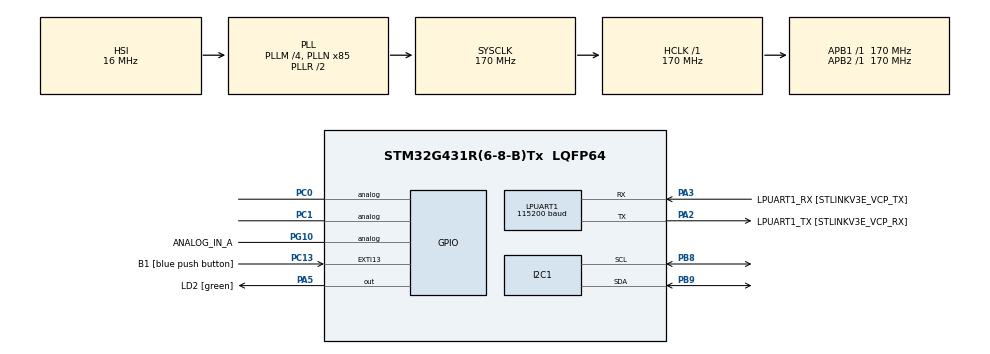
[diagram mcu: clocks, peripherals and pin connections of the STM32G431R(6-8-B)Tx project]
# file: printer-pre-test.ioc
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I2C1.Timing=0x30A0A7FB
LPUART1.BaudRate=115200
LPUART1.WordLength=UART_WORDLENGTH_8B
Mcu.Family=STM32G4
Mcu.Name=STM32G431R(6-8-B)Tx
Mcu.Package=LQFP64
NVIC.PriorityGroup=NVIC_PRIORITYGROUP_4
PA13.GPIO_Label=T_SWDIO
PA13.Mode=Serial_Wire
PA13.Signal=SYS_JTMS-SWDIO
PA14.GPIO_Label=T_SWCLK
PA14.Mode=Serial_Wire
PA14.Signal=SYS_JTCK-SWCLK
PA2.GPIO_Label=LPUART1_TX [STLINKV3E_VCP_RX]
PA2.Mode=Asynchronous
PA2.Signal=LPUART1_TX
PA3.GPIO_Label=LPUART1_RX [STLINKV3E_VCP_TX]
PA3.Mode=Asynchronous
PA3.Signal=LPUART1_RX
PA5.GPIO_Label=LD2 [green]
PA5.Signal=GPIO_Output
PB3.GPIO_Label=T_SWO
PB3.Signal=SYS_JTDO-SWO
PB8-BOOT0.Mode=I2C
PB8-BOOT0.Signal=I2C1_SCL
PB9.Mode=I2C
PB9.Signal=I2C1_SDA
PC0.Signal=GPIO_Analog
PC1.Signal=GPIO_Analog
PC13.GPIO_Label=B1 [blue push button]
PC13.Signal=GPXTI13
PC14-OSC32_IN.Mode=LSE-External-Oscillator
PC14-OSC32_IN.Signal=RCC_OSC32_IN
PC15-OSC32_OUT.Mode=LSE-External-Oscillator
PC15-OSC32_OUT.Signal=RCC_OSC32_OUT
PF0-OSC_IN.Mode=HSE-External-Oscillator
PF0-OSC_IN.Signal=RCC_OSC_IN
PF1-OSC_OUT.Mode=HSE-External-Oscillator
PF1-OSC_OUT.Signal=RCC_OSC_OUT
PG10-NRST.GPIO_Label=ANALOG_IN_A
PG10-NRST.Signal=GPIO_Analog
ProjectManager.HeapSize=0x200
ProjectManager.StackSize=0x400
ProjectManager.TargetToolchain=STM32CubeIDE
RCC.ADC12Freq_Value=170000000
RCC.AHBFreq_Value=170000000
RCC.APB1Freq_Value=170000000
RCC.APB1TimFreq_Value=170000000
RCC.APB2Freq_Value=170000000
RCC.APB2TimFreq_Value=170000000
RCC.CortexFreq_Value=170000000
RCC.EXTERNAL_CLOCK_VALUE=12288000
RCC.HCLKFreq_Value=170000000
RCC.HSE_VALUE=24000000
RCC.HSI48_VALUE=48000000
RCC.HSI_VALUE=16000000
RCC.PLLM=RCC_PLLM_DIV4
RCC.PLLN=85
RCC.RTCClockSelection=RCC_RTCCLKSOURCE_LSE
RCC.SYSCLKFreq_VALUE=170000000
RCC.SYSCLKSource=RCC_SYSCLKSOURCE_PLLCLK
RCC.USBFreq_Value=170000000
RCC.VCOOutputFreq_Value=340000000
VP_SYS_VS_DBSignals.Mode=DisableDeadBatterySignals
board=NUCLEO-G431RB

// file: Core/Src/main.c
/* USER CODE BEGIN Header */
/**
 ******************************************************************************
 * @file           : main.c
 * @brief          : Main program body
 ******************************************************************************
 * @attention
 *
 * Copyright (c) 2021 STMicroelectronics.
 * All rights reserved.
 *
 * This software is licensed under terms that can be found in the LICENSE file
 * in the root directory of this software component.
 * If no LICENSE file comes with this software, it is provided AS-IS.
 *
 ******************************************************************************
 */
/* USER CODE END Header */
#include "main.h"

/* USER CODE BEGIN Includes */

#include <string.h>

#include "custom.h"

/* USER CODE END Includes */

I2C_HandleTypeDef hi2c1;

UART_HandleTypeDef hlpuart1;

void SystemClock_Config(void);
static void MX_GPIO_Init(void);
static void MX_LPUART1_UART_Init(void);
static void MX_I2C1_Init(void);

int main(void)
{
  /* USER CODE BEGIN 1 */

	custom_setup_debug_uart(&hlpuart1);

  /* USER CODE END 1 */

  /* MCU Configuration--------------------------------------------------------*/

  /* Reset of all peripherals, Initializes the Flash interface and the Systick. */
  HAL_Init();

  /* Configure the system clock */
  SystemClock_Config();

  /* Initialize all configured peripherals */
  MX_GPIO_Init();
  MX_LPUART1_UART_Init();
  MX_I2C1_Init();

  /* Infinite loop */
  /* USER CODE BEGIN WHILE */
	while (1) {
		custom_tick();
    /* USER CODE END WHILE */

	}
}

void SystemClock_Config(void)
{
  RCC_OscInitTypeDef RCC_OscInitStruct = {0};
  RCC_ClkInitTypeDef RCC_ClkInitStruct = {0};

  /** Configure the main internal regulator output voltage
  */
  HAL_PWREx_ControlVoltageScaling(PWR_REGULATOR_VOLTAGE_SCALE1_BOOST);
  /** Initializes the RCC Oscillators according to the specified parameters
  * in the RCC_OscInitTypeDef structure.
  */
  RCC_OscInitStruct.OscillatorType = RCC_OSCILLATORTYPE_HSI;
  RCC_OscInitStruct.HSIState = RCC_HSI_ON;
  RCC_OscInitStruct.HSICalibrationValue = RCC_HSICALIBRATION_DEFAULT;
  RCC_OscInitStruct.PLL.PLLState = RCC_PLL_ON;
  RCC_OscInitStruct.PLL.PLLSource = RCC_PLLSOURCE_HSI;
  RCC_OscInitStruct.PLL.PLLM = RCC_PLLM_DIV4;
  RCC_OscInitStruct.PLL.PLLN = 85;
  RCC_OscInitStruct.PLL.PLLP = RCC_PLLP_DIV2;
  RCC_OscInitStruct.PLL.PLLQ = RCC_PLLQ_DIV2;
  RCC_OscInitStruct.PLL.PLLR = RCC_PLLR_DIV2;
  if (HAL_RCC_OscConfig(&RCC_OscInitStruct) != HAL_OK)
  {
    Error_Handler();
  }
  /** Initializes the CPU, AHB and APB buses clocks
  */
  RCC_ClkInitStruct.ClockType = RCC_CLOCKTYPE_HCLK|RCC_CLOCKTYPE_SYSCLK
                              |RCC_CLOCKTYPE_PCLK1|RCC_CLOCKTYPE_PCLK2;
  RCC_ClkInitStruct.SYSCLKSource = RCC_SYSCLKSOURCE_PLLCLK;
  RCC_ClkInitStruct.AHBCLKDivider = RCC_SYSCLK_DIV1;
  RCC_ClkInitStruct.APB1CLKDivider = RCC_HCLK_DIV1;
  RCC_ClkInitStruct.APB2CLKDivider = RCC_HCLK_DIV1;

  if (HAL_RCC_ClockConfig(&RCC_ClkInitStruct, FLASH_LATENCY_4) != HAL_OK)
  {
    Error_Handler();
  }
}

static void MX_I2C1_Init(void)
{

  hi2c1.Instance = I2C1;
  hi2c1.Init.Timing = 0x30A0A7FB;
  hi2c1.Init.OwnAddress1 = 0;
  hi2c1.Init.AddressingMode = I2C_ADDRESSINGMODE_7BIT;
  hi2c1.Init.DualAddressMode = I2C_DUALADDRESS_DISABLE;
  hi2c1.Init.OwnAddress2 = 0;
  hi2c1.Init.OwnAddress2Masks = I2C_OA2_NOMASK;
  hi2c1.Init.GeneralCallMode = I2C_GENERALCALL_DISABLE;
  hi2c1.Init.NoStretchMode = I2C_NOSTRETCH_DISABLE;
  if (HAL_I2C_Init(&hi2c1) != HAL_OK)
  {
    Error_Handler();
  }
  /** Configure Analogue filter
  */
  if (HAL_I2CEx_ConfigAnalogFilter(&hi2c1, I2C_ANALOGFILTER_ENABLE) != HAL_OK)
  {
    Error_Handler();
  }
  /** Configure Digital filter
  */
  if (HAL_I2CEx_ConfigDigitalFilter(&hi2c1, 0) != HAL_OK)
  {
    Error_Handler();
  }

}

static void MX_LPUART1_UART_Init(void)
{

  hlpuart1.Instance = LPUART1;
  hlpuart1.Init.BaudRate = 115200;
  hlpuart1.Init.WordLength = UART_WORDLENGTH_8B;
  hlpuart1.Init.StopBits = UART_STOPBITS_1;
  hlpuart1.Init.Parity = UART_PARITY_NONE;
  hlpuart1.Init.Mode = UART_MODE_TX_RX;
  hlpuart1.Init.HwFlowCtl = UART_HWCONTROL_NONE;
  hlpuart1.Init.OneBitSampling = UART_ONE_BIT_SAMPLE_DISABLE;
  hlpuart1.Init.ClockPrescaler = UART_PRESCALER_DIV1;
  hlpuart1.AdvancedInit.AdvFeatureInit = UART_ADVFEATURE_NO_INIT;
  if (HAL_UART_Init(&hlpuart1) != HAL_OK)
  {
    Error_Handler();
  }
  if (HAL_UARTEx_SetTxFifoThreshold(&hlpuart1, UART_TXFIFO_THRESHOLD_1_8) != HAL_OK)
  {
    Error_Handler();
  }
  if (HAL_UARTEx_SetRxFifoThreshold(&hlpuart1, UART_RXFIFO_THRESHOLD_1_8) != HAL_OK)
  {
    Error_Handler();
  }
  if (HAL_UARTEx_DisableFifoMode(&hlpuart1) != HAL_OK)
  {
    Error_Handler();
  }

}

static void MX_GPIO_Init(void)
{
  GPIO_InitTypeDef GPIO_InitStruct = {0};

  /* GPIO Ports Clock Enable */
  __HAL_RCC_GPIOC_CLK_ENABLE();
  __HAL_RCC_GPIOF_CLK_ENABLE();
  __HAL_RCC_GPIOG_CLK_ENABLE();
  __HAL_RCC_GPIOA_CLK_ENABLE();
  __HAL_RCC_GPIOB_CLK_ENABLE();

  /*Configure GPIO pin Output Level */
  HAL_GPIO_WritePin(LD2_GPIO_Port, LD2_Pin, GPIO_PIN_RESET);

  /*Configure GPIO pin : B1_Pin */
  GPIO_InitStruct.Pin = B1_Pin;
  GPIO_InitStruct.Mode = GPIO_MODE_IT_RISING;
  GPIO_InitStruct.Pull = GPIO_NOPULL;
  HAL_GPIO_Init(B1_GPIO_Port, &GPIO_InitStruct);

  /*Configure GPIO pin : ANALOG_IN_A_Pin */
  GPIO_InitStruct.Pin = ANALOG_IN_A_Pin;
  GPIO_InitStruct.Mode = GPIO_MODE_ANALOG;
  GPIO_InitStruct.Pull = GPIO_NOPULL;
  HAL_GPIO_Init(ANALOG_IN_A_GPIO_Port, &GPIO_InitStruct);

  /*Configure GPIO pins : PC0 PC1 */
  GPIO_InitStruct.Pin = GPIO_PIN_0|GPIO_PIN_1;
  GPIO_InitStruct.Mode = GPIO_MODE_ANALOG;
  GPIO_InitStruct.Pull = GPIO_NOPULL;
  HAL_GPIO_Init(GPIOC, &GPIO_InitStruct);

  /*Configure GPIO pin : LD2_Pin */
  GPIO_InitStruct.Pin = LD2_Pin;
  GPIO_InitStruct.Mode = GPIO_MODE_OUTPUT_PP;
  GPIO_InitStruct.Pull = GPIO_NOPULL;
  GPIO_InitStruct.Speed = GPIO_SPEED_FREQ_LOW;
  HAL_GPIO_Init(LD2_GPIO_Port, &GPIO_InitStruct);

}

void Error_Handler(void)
{
	__disable_irq();
	while (1) {
	}
}
